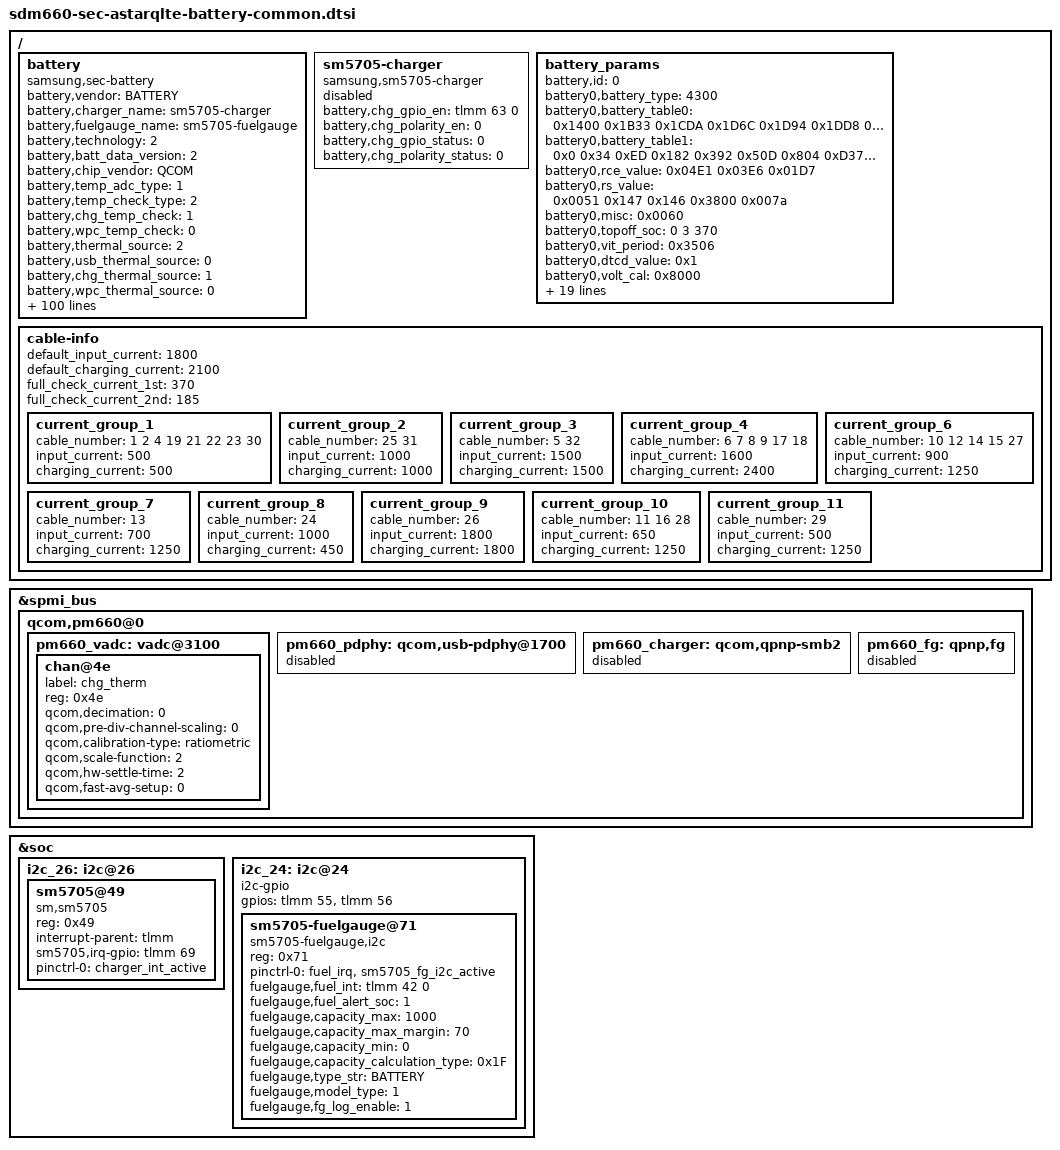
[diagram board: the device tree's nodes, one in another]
/* Copyright (c) 2014, The Linux Foundation. All rights reserved.
 *
 * This program is free software; you can redistribute it and/or modify
 * it under the terms of the GNU General Public License version 2 and
 * only version 2 as published by the Free Software Foundation.
 *
 * This program is distributed in the hope that it will be useful,
 * but WITHOUT ANY WARRANTY; without even the implied warranty of
 * MERCHANTABILITY or FITNESS FOR A PARTICULAR PURPOSE.  See the
 * GNU General Public License for more details.
 */

&spmi_bus {
	qcom,pm660@0 {
		pm660_vadc: vadc@3100 {
			chan@4e { /* AMUX_2 */
				label = "chg_therm";
				reg = <0x4e>;
				qcom,decimation = <0>;
				qcom,pre-div-channel-scaling = <0>;
				qcom,calibration-type = "ratiometric";
				qcom,scale-function = <2>;
				qcom,hw-settle-time = <2>;
				qcom,fast-avg-setup = <0>;
			};
		};
		pm660_pdphy: qcom,usb-pdphy@1700 {
			status = "disabled";
		};
		pm660_charger: qcom,qpnp-smb2 {
			status = "disabled";
		};
		pm660_fg: qpnp,fg {
			status = "disabled";
		};
		/delete-node/bcl@4200;
	};
};

&soc {
	i2c_26: i2c@26 {
		sm5705@49{
			compatible = "sm,sm5705";
			reg = <0x49>;
			interrupt-parent = <&tlmm>;
			sm5705,irq-gpio = <&tlmm 69 0x00>;
			pinctrl-names = "default";
			pinctrl-0 = <&charger_int_active>;
/*			sm5705,mrstb-gpio = <&tlmm 87 0x00>;*/
		};
	};
	i2c_24: i2c@24 {
		compatible = "i2c-gpio";
		gpios = <&tlmm 55 0 /* sda */
			&tlmm 56 0 /* scl */
			>;
		#address-cells = <1>;
		#size-cells = <0>;

		sm5705-fuelgauge@71 {
			compatible = "sm5705-fuelgauge,i2c";
			reg = <0x71>;
			pinctrl-names = "default";
			pinctrl-0 = <&fuel_irq &sm5705_fg_i2c_active>;
			fuelgauge,fuel_int = <&tlmm 42 0>;
			fuelgauge,fuel_alert_soc = <1>;
			fuelgauge,capacity_max = <1000>;
			fuelgauge,capacity_max_margin = <70>;
			fuelgauge,capacity_min = <0>;
			fuelgauge,capacity_calculation_type = <0x1F>;
			fuelgauge,type_str = "BATTERY";
			fuelgauge,model_type = <1>;
			fuelgauge,fg_log_enable = <1>;
		};
	};

	/delete-node/qcom,bcl;
};

/{
	battery {
		status = "okay";
		compatible = "samsung,sec-battery";
		battery,vendor = "BATTERY";
		battery,charger_name = "sm5705-charger";
		battery,fuelgauge_name = "sm5705-fuelgauge";
		battery,technology = <2>; /* POWER_SUPPLY_TECHNOLOGY_LION */

		battery,batt_data_version = <2>;

		battery,chip_vendor = "QCOM";
		battery,temp_adc_type = <1>; /* SEC_BATTERY_ADC_TYPE_AP */

		battery,temp_check_type = <2>; /* SEC_BATTERY_TEMP_CHECK_TEMP */
		battery,chg_temp_check = <1>;
		battery,wpc_temp_check = <0>;

		battery,thermal_source = <2>; /* SEC_BATTERY_THERMAL_SOURCE_ADC */
		battery,usb_thermal_source = <0>; /* SEC_BATTERY_THERMAL_SOURCE_ADC */
		battery,chg_thermal_source = <1>;
		battery,wpc_thermal_source = <0>;
		battery,coil_thermal_source = <0>;

		battery,polling_time = <10 30 30 30 3600>;

		battery,temp_table_adc = <1145 1345 1575 1868 2385 2763 2953 3451 4024 4693 5505 6207 7079 7947 8810 9773 10797 11679 12516 13278 13926 14472 14927>;
		battery,temp_table_data = <900 850 800 750 700 650 600 550 500 450 400 350 300 250 200 150 100 50 0 (-50) (-100) (-150) (-200)>;
		battery,chg_temp_table_adc = <1097 1326 1536 1837 2374 2747 2972 3477 4055 4736 5474 6267 7142 8017 8875 9843 10856 11743 12556 13315 13957 14489 14919>;
		battery,chg_temp_table_data = <900 850 800 750 700 650 600 550 500 450 400 350 300 250 200 150 100 50 0 (-50) (-100) (-150) (-200)>;

		battery,adc_check_count = <5>;

		battery,cable_check_type = <4>; /* SEC_BATTERY_CABLE_CHECK_PSY */
		battery,cable_source_type = <1>; /* SEC_BATTERY_CABLE_SOURCE_EXTERNAL */
		battery,polling_type = <1>; /* SEC_BATTERY_MONITOR_ALARM */
		battery,monitor_initial_count = <0>;

		battery,battery_check_type = <0>; /* SEC_BATTERY_CHECK_NONE */
		battery,check_count = <0>;
		battery,check_adc_max = <1440>;
		battery,check_adc_min = <0>;

		battery,ovp_uvlo_check_type = <3>; /* SEC_BATTERY_OVP_UVLO_CHGPOLLING */

		battery,temp_check_count = <1>;
		battery,temp_highlimit_threshold_event = <800>;
		battery,temp_highlimit_recovery_event = <750>;
		battery,temp_high_threshold_event = <500>;
		battery,temp_high_recovery_event = <450>;
		battery,temp_low_threshold_event = <0>;
		battery,temp_low_recovery_event = <50>;
		battery,temp_highlimit_threshold_normal = <800>;
		battery,temp_highlimit_recovery_normal = <750>;
		battery,temp_high_threshold_normal = <500>;
		battery,temp_high_recovery_normal = <450>;
		battery,temp_low_threshold_normal = <0>;
		battery,temp_low_recovery_normal = <50>;
		battery,temp_highlimit_threshold_lpm = <800>;
		battery,temp_highlimit_recovery_lpm = <750>;
		battery,temp_high_threshold_lpm = <500>;
		battery,temp_high_recovery_lpm = <450>;
		battery,temp_low_threshold_lpm = <0>;
		battery,temp_low_recovery_lpm = <50>;
		battery,full_check_type = <2>; /* SEC_BATTERY_FULLCHARGED_FG_CURRENT */
		battery,full_check_type_2nd = <2>; /* SEC_BATTERY_FULLCHARGED_FG_CURRENT */
		battery,full_check_count = <3>;
		battery,chg_gpio_full_check = <0>;
		battery,chg_polarity_full_check = <1>;

		battery,chg_high_temp = <460>;
		battery,chg_high_temp_recovery = <440>;
		battery,chg_input_limit_current = <1000>;
		battery,chg_charging_limit_current = <1250>;

		battery,mix_high_temp = <420>;
		battery,mix_high_chg_temp = <500>;
		battery,mix_high_temp_recovery = <390>;

		/* SEC_BATTERY_FULL_CONDITION_NOTIMEFULL |
		   SEC_BATTERY_FULL_CONDITION_VCELL */
		battery,full_condition_type = <9>;
		battery,full_condition_soc = <93>;
		battery,full_condition_vcell = <4250>;

		battery,recharge_check_count = <1>;
		battery,recharge_condition_type = <4>; /* SEC_BATTERY_RECHARGE_CONDITION_VCELL */
		battery,recharge_condition_soc = <98>;
		battery,recharge_condition_vcell = <4280>;

		battery,standard_curr = <2400>;
		battery,expired_time = <10800>;
		battery,recharging_expired_time = <5400>;
		battery,charging_reset_time = <0>;
		qcom,sec-battery-vadc = <&pm660_vadc>;

		battery,chg_float_voltage = <4350>;

		battery,pre_afc_work_delay = <2000>;
		battery,pre_afc_input_current = <500>;

		battery,swelling_high_temp_block = <410>;
		battery,swelling_high_temp_recov = <390>;
		battery,swelling_low_temp_block_1st = <150>;
		battery,swelling_low_temp_recov_1st = <200>;
		battery,swelling_low_temp_block_2nd = <50>;
		battery,swelling_low_temp_recov_2nd = <100>;
		battery,swelling_low_temp_current = <850>;	/* 0.3C */ /* Max charge current 2960mA (0.8C) */
		battery,swelling_low_temp_topoff = <185>;	/* 0.05C */
		battery,swelling_high_temp_current = <1300>;	/* 0.45C */
		battery,swelling_high_temp_topoff = <185>;	/* 0.05C */
		battery,swelling_drop_float_voltage = <4150>;
		battery,swelling_high_rechg_voltage = <4000>;
		battery,swelling_low_rechg_voltage = <4000>;

		battery,siop_event_check_type = <1>;
		battery,siop_call_cv_current = <330>;
		battery,siop_call_cc_current = <330>;

		battery,siop_input_limit_current = <1200>;
		battery,siop_charging_limit_current = <1000>;
		battery,siop_hv_input_limit_current = <500>;
		battery,siop_hv_charging_limit_current = <1000>;

		/* cycle, chg_float_voltage, recharge_condition_vcell, full_condition_vcell, full_condition_soc */
		battery,age_data = <0 4350 4280 4250 93
				200 4330 4260 4225 92
				250 4310 4240 4212 91
				300 4290 4220 4187 90
				1000 4240 4170 4137 89>;

		battery,pd_charging_charge_power = <15000>;
		battery,max_input_voltage = <9000>; /* mV */
		battery,max_input_current = <3000>;  /* mA */
		battery,max_charging_current = <2400>;

		battery,enable_sysovlo_irq;

		battery,battery_full_capacity = <3700>; /* battery capacity */
		battery,cisd_qh_current_low_thr = <190>;
		battery,cisd_qh_current_high_thr = <210>;
		battery,cisd_qh_vfsoc_thr = <100000>; /* 0.001% */
		/* disable Vbat ovp dettection */
		battery,cisd_max_voltage_thr = <5000>; /* batttery ovp dettection voltage */
		battery,cisd_alg_index = <7>;
		battery,full_chg_current_margin = <0>;
	};
	
	sm5705-charger {
		status = "disable";
		compatible = "samsung,sm5705-charger";
		battery,chg_gpio_en = <&tlmm 63 0>;
		battery,chg_polarity_en = <0>;
		battery,chg_gpio_status = <0>;
		battery,chg_polarity_status = <0>;
	};
	
	battery_params {
		battery,id = <0>; /* -1 means auto, detected by F/G */
		battery0,battery_type = <4300>; /* 4200 4350 4400 */
		battery0,battery_table0 = <0x1400 0x1B33 0x1CDA 0x1D6C 0x1D94 0x1DD8 0x1E26 0x1E8A 0x1ED0 0x1F89 0x1FBE 0x2012 0x2071 0x20F1 0x225F 0x2400>;
		battery0,battery_table1 = <0x0 0x34 0xED 0x182 0x392 0x50D 0x804 0xD37 0xF6C 0x1263 0x13DE 0x1559 0x1613 0x1850 0x1D0C 0x1D13>;
		battery0,rce_value = <0x04E1 0x03E6 0x01D7>;
		battery0,rs_value = <0x0051 0x147 0x146 0x3800 0x007a>; /*rs p_mix_factor n_mix_factor max min*/
		battery0,misc = <0x0060>;
		battery0,topoff_soc = <0 3 370>; /*disable soc current*/
		battery0,vit_period = <0x3506>;
		battery0,dtcd_value = <0x1>;
		battery0,volt_cal = <0x8000>;
		battery0,curr_offset = <1 0x0000>; /*en_auto offset*/
		battery0,p_curr_cal = <0x0088>;
		battery0,n_curr_cal = <0x0084>;
		battery0,mix_value = <0x0403 0x0004>; /*mix_rate init_blank*/
		battery0,temp_std = <25>;
		battery0,temp_cal = <1 6 1 11 (-1) 1 6 1 9 1>; /* en_h, p_de, p_fa, n_de, n_fa, en_l, p_de, p_fa, n_de, n_fa, */
		battery0,ext_temp_cal = <1 3 0 3 1 1 2 3 2 3>; /* en_h, p_de, p_fa, n_de, n_fa, en_l, p_de, p_fa, n_de, n_fa, */
		battery0,temp_volcal = <1 45 1>; /* en, temp, cal */
		battery0,temp_offset = <1 11 1 1 8 (-1)>; /* en_high level offset en_low level offset */
		battery0,cycle_cfg = <7 1 3>; /*high_limit low_limit cntl*/
		battery0,curr_lcal = <0 0x8888 0x8888 0x8888>;
		battery0,tem_poff = <3380 50 3320 50>;
		battery0,v_offset_cancel = <1 0 100 2>; /* en_p, en_n, level, mohm */
		battery0,v_alarm = <3000>;
		battery0,v_max_table = <0x225F 0x2239 0x2213 0x21ED 0x218D>;
		battery0,q_max_table = <0x1D0C 0x1C87 0x1C03 0x1B7E 0x1A33>;
		battery0,data_ver = <0x03>;
	};

/* sec_battery_cable
 *   0	UNKNOWN,
 *   1	NONE,
 *   2	PREPARE_TA,
 *   3	TA,
 *   4	USB,
 *   5	USB_CDP,
 *   6	9V_TA,
 *   7	9V_ERR,
 *   8	9V_UNKNOWN,
 *   9	12V_TA,
 *  10	WIRELESS,
 *  11	HV_WIRELESS,
 *  12	PMA_WIRELESS,
 *  13	WIRELESS_PACK,
 *  14	WIRELESS_PACK_TA,
 *  15	WIRELESS_STAND,
 *  16	WIRELESS_HV_STAND,
 *  17	QC20,
 *  18	QC30,
 *  19	PDIC,
 *  20	UARTOFF,
 *  21	OTG,
 *  22	LAN_HUB,
 *  23	POWER_SHARING,
 *  24	HMT_CONNECTED,
 *  25	HMT_CHARGE,
 *  26	HV_TA_CHG_LIMIT,
 *  27	WIRELESS_VEHICLE,
 *  28	WIRELESS_HV_VEHICLE,
 *  29	PREPARE_WIRELESS_HV,
 *  30  TIMEOUT,
 *  31  SMART_OTG,
 *  32  SMART_NOTG,
 *  33	CABLE_MAX,
 */
	cable-info {
		default_input_current = <1800>;
		default_charging_current = <2100>;
		full_check_current_1st = <370>;
		full_check_current_2nd = <185>;

		current_group_1 {
			cable_number = <1 2 4 19 21 22 23 30>;
			input_current = <500>;
			charging_current = <500>;
		};
		current_group_2 {
			cable_number = <25 31>;
			input_current = <1000>;
			charging_current = <1000>;
		};
		current_group_3 {
			cable_number = <5 32>;
			input_current = <1500>;
			charging_current = <1500>;
		};
		current_group_4 {
			cable_number = <6 7 8 9 17 18>;
			input_current = <1600>;
			charging_current = <2400>;
		};
		current_group_6 {
			cable_number = <10 12 14 15 27>;
			input_current = <900>;
			charging_current = <1250>;
		};
		current_group_7 {
			cable_number = <13>;
			input_current = <700>;
			charging_current = <1250>;
		};
		current_group_8 {
			cable_number = <24>;
			input_current = <1000>;
			charging_current = <450>;
		};
		current_group_9 {
			cable_number = <26>;
			input_current = <1800>;
			charging_current = <1800>;
		};
		current_group_10 {
			cable_number = <11 16 28>;
			input_current = <650>;
			charging_current = <1250>;
		};
		current_group_11 {
			cable_number = <29>;
			input_current = <500>;
			charging_current = <1250>;
		};
	};
};
